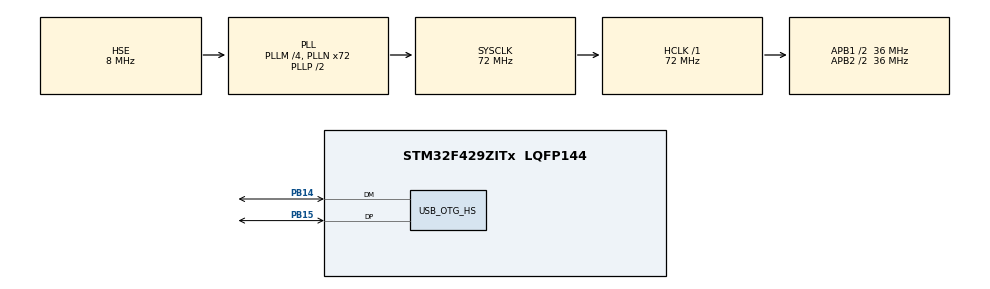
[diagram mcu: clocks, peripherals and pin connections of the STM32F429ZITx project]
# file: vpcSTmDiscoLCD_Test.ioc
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Mcu.Family=STM32F4
Mcu.Name=STM32F429ZITx
Mcu.Package=LQFP144
NVIC.OTG_HS_IRQn=true\:0\:0\:false\:false\:true\:false\:true
NVIC.PriorityGroup=NVIC_PRIORITYGROUP_4
PA13.Mode=Serial_Wire
PA13.Signal=SYS_JTMS-SWDIO
PA14.Mode=Serial_Wire
PA14.Signal=SYS_JTCK-SWCLK
PB14.Mode=Device_Only_FS
PB14.Signal=USB_OTG_HS_DM
PB15.Mode=Device_Only_FS
PB15.Signal=USB_OTG_HS_DP
PH0/OSC_IN.Mode=HSE-External-Oscillator
PH0/OSC_IN.Signal=RCC_OSC_IN
PH1/OSC_OUT.Mode=HSE-External-Oscillator
PH1/OSC_OUT.Signal=RCC_OSC_OUT
ProjectManager.HeapSize=0x2000
ProjectManager.StackSize=0x4000
ProjectManager.TargetToolchain=MDK-ARM V5.27
RCC.48MHZClocksFreq_Value=48000000
RCC.AHBFreq_Value=72000000
RCC.APB1CLKDivider=RCC_HCLK_DIV2
RCC.APB1Freq_Value=36000000
RCC.APB1TimFreq_Value=72000000
RCC.APB2CLKDivider=RCC_HCLK_DIV2
RCC.APB2Freq_Value=36000000
RCC.APB2TimFreq_Value=72000000
RCC.CortexFreq_Value=72000000
RCC.HCLKFreq_Value=72000000
RCC.HSE_VALUE=8000000
RCC.HSI_VALUE=16000000
RCC.LSE_VALUE=32768
RCC.PLLM=4
RCC.PLLN=72
RCC.PLLQ=3
RCC.SYSCLKFreq_VALUE=72000000
RCC.SYSCLKSource=RCC_SYSCLKSOURCE_PLLCLK
RCC.VCOOutputFreq_Value=144000000
USB_DEVICE.CLASS_NAME_HS=CDC
USB_DEVICE.VirtualMode-CDC_HS=Cdc
USB_DEVICE.VirtualModeHS=Cdc_HS
USB_OTG_HS.VirtualMode-Device_Only_FS=Device_Only_FS
VP_USB_DEVICE_VS_USB_DEVICE_CDC_HS.Mode=CDC_HS
board=custom

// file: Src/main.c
/* USER CODE BEGIN Header */
/**
  ******************************************************************************
  * @file           : main.c
  * @brief          : Main program body
  ******************************************************************************
  * @attention
  *
  * <h2><center>&copy; Copyright (c) 2020 STMicroelectronics.
  * All rights reserved.</center></h2>
  *
  * This software component is licensed by ST under Ultimate Liberty license
  * SLA0044, the "License"; You may not use this file except in compliance with
  * the License. You may obtain a copy of the License at:
  *                             www.st.com/SLA0044
  *
  ******************************************************************************
  */
/* USER CODE END Header */

#include "main.h"
#include "usb_device.h"
#include "gpio.h"

/* USER CODE BEGIN Includes */
#include "usbd_cdc_if.h"
#include<string.h>
/* USER CODE END Includes */

void SystemClock_Config(void);

int main(void)
{
  /* USER CODE BEGIN 1 */
	char myBuff[20];
	uint32_t cnt = 0;
  /* USER CODE END 1 */

  /* MCU Configuration--------------------------------------------------------*/

  /* Reset of all peripherals, Initializes the Flash interface and the Systick. */
  HAL_Init();

  /* Configure the system clock */
  SystemClock_Config();

  /* Initialize all configured peripherals */
  MX_GPIO_Init();
  MX_USB_DEVICE_Init();

  /* Infinite loop */
  while (1)
  {

    /* USER CODE BEGIN 3 */
			cnt = cnt + 1;
		sprintf(myBuff,"Data = %d\n\r", cnt);
		CDC_Transmit_HS((uint8_t *)myBuff,strlen(myBuff));
		HAL_Delay(200);
  }
  /* USER CODE END 3 */
}

void SystemClock_Config(void)
{
  RCC_OscInitTypeDef RCC_OscInitStruct = {0};
  RCC_ClkInitTypeDef RCC_ClkInitStruct = {0};

  /** Configure the main internal regulator output voltage
  */
  __HAL_RCC_PWR_CLK_ENABLE();
  __HAL_PWR_VOLTAGESCALING_CONFIG(PWR_REGULATOR_VOLTAGE_SCALE3);
  /** Initializes the CPU, AHB and APB busses clocks
  */
  RCC_OscInitStruct.OscillatorType = RCC_OSCILLATORTYPE_HSE;
  RCC_OscInitStruct.HSEState = RCC_HSE_ON;
  RCC_OscInitStruct.PLL.PLLState = RCC_PLL_ON;
  RCC_OscInitStruct.PLL.PLLSource = RCC_PLLSOURCE_HSE;
  RCC_OscInitStruct.PLL.PLLM = 4;
  RCC_OscInitStruct.PLL.PLLN = 72;
  RCC_OscInitStruct.PLL.PLLP = RCC_PLLP_DIV2;
  RCC_OscInitStruct.PLL.PLLQ = 3;
  if (HAL_RCC_OscConfig(&RCC_OscInitStruct) != HAL_OK)
  {
    Error_Handler();
  }
  /** Initializes the CPU, AHB and APB busses clocks
  */
  RCC_ClkInitStruct.ClockType = RCC_CLOCKTYPE_HCLK|RCC_CLOCKTYPE_SYSCLK
                              |RCC_CLOCKTYPE_PCLK1|RCC_CLOCKTYPE_PCLK2;
  RCC_ClkInitStruct.SYSCLKSource = RCC_SYSCLKSOURCE_PLLCLK;
  RCC_ClkInitStruct.AHBCLKDivider = RCC_SYSCLK_DIV1;
  RCC_ClkInitStruct.APB1CLKDivider = RCC_HCLK_DIV2;
  RCC_ClkInitStruct.APB2CLKDivider = RCC_HCLK_DIV2;

  if (HAL_RCC_ClockConfig(&RCC_ClkInitStruct, FLASH_LATENCY_2) != HAL_OK)
  {
    Error_Handler();
  }
}

void Error_Handler(void)
{
}

/************************ (C) COPYRIGHT STMicroelectronics *****END OF FILE****/
